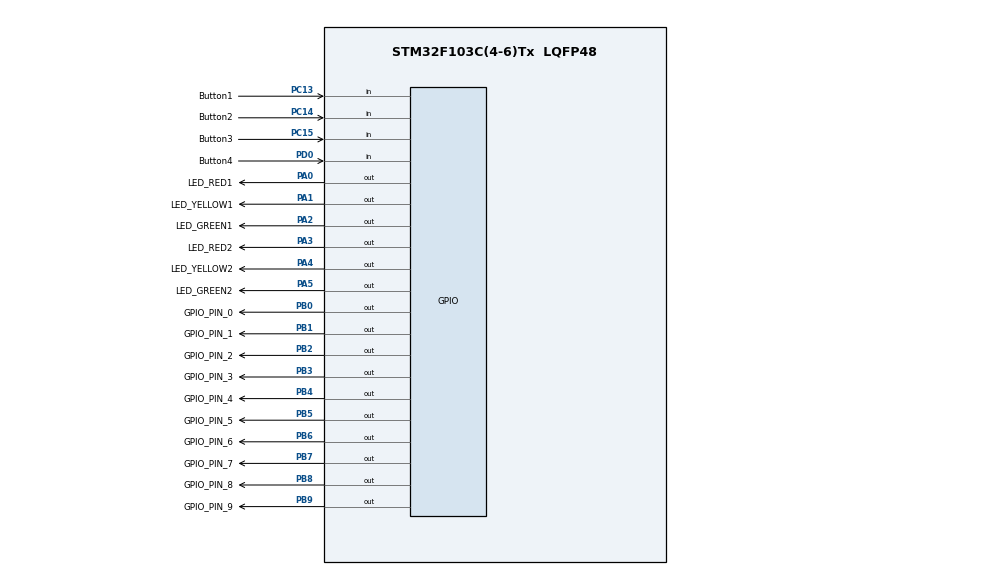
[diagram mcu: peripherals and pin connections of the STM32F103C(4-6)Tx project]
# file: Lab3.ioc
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Mcu.Family=STM32F1
Mcu.Name=STM32F103C(4-6)Tx
Mcu.Package=LQFP48
NVIC.PriorityGroup=NVIC_PRIORITYGROUP_4
NVIC.TIM2_IRQn=true\:0\:0\:false\:false\:true\:true\:true
PA0-WKUP.GPIO_Label=LED_RED1
PA0-WKUP.Signal=GPIO_Output
PA1.GPIO_Label=LED_YELLOW1
PA1.Signal=GPIO_Output
PA13.Mode=Serial_Wire
PA13.Signal=SYS_JTMS-SWDIO
PA14.Mode=Serial_Wire
PA14.Signal=SYS_JTCK-SWCLK
PA2.GPIO_Label=LED_GREEN1
PA2.Signal=GPIO_Output
PA3.GPIO_Label=LED_RED2
PA3.Signal=GPIO_Output
PA4.GPIO_Label=LED_YELLOW2
PA4.Signal=GPIO_Output
PA5.GPIO_Label=LED_GREEN2
PA5.Signal=GPIO_Output
PB0.GPIO_Label=GPIO_PIN_0
PB0.PinState=GPIO_PIN_SET
PB0.Signal=GPIO_Output
PB1.GPIO_Label=GPIO_PIN_1
PB1.PinState=GPIO_PIN_SET
PB1.Signal=GPIO_Output
PB2.GPIO_Label=GPIO_PIN_2
PB2.PinState=GPIO_PIN_SET
PB2.Signal=GPIO_Output
PB3.GPIO_Label=GPIO_PIN_3
PB3.PinState=GPIO_PIN_SET
PB3.Signal=GPIO_Output
PB4.GPIO_Label=GPIO_PIN_4
PB4.PinState=GPIO_PIN_SET
PB4.Signal=GPIO_Output
PB5.GPIO_Label=GPIO_PIN_5
PB5.PinState=GPIO_PIN_SET
PB5.Signal=GPIO_Output
PB6.GPIO_Label=GPIO_PIN_6
PB6.PinState=GPIO_PIN_SET
PB6.Signal=GPIO_Output
PB7.GPIO_Label=GPIO_PIN_7
PB7.PinState=GPIO_PIN_SET
PB7.Signal=GPIO_Output
PB8.GPIO_Label=GPIO_PIN_8
PB8.PinState=GPIO_PIN_SET
PB8.Signal=GPIO_Output
PB9.GPIO_Label=GPIO_PIN_9
PB9.PinState=GPIO_PIN_SET
PB9.Signal=GPIO_Output
PC13-TAMPER-RTC.GPIO_Label=Button1
PC13-TAMPER-RTC.GPIO_PuPd=GPIO_PULLUP
PC13-TAMPER-RTC.Signal=GPIO_Input
PC14-OSC32_IN.GPIO_Label=Button2
PC14-OSC32_IN.GPIO_PuPd=GPIO_PULLUP
PC14-OSC32_IN.Signal=GPIO_Input
PC15-OSC32_OUT.GPIO_Label=Button3
PC15-OSC32_OUT.GPIO_PuPd=GPIO_PULLUP
PC15-OSC32_OUT.Signal=GPIO_Input
PD0-OSC_IN.GPIO_Label=Button4
PD0-OSC_IN.GPIO_PuPd=GPIO_PULLUP
PD0-OSC_IN.Signal=GPIO_Input
ProjectManager.HeapSize=0x200
ProjectManager.StackSize=0x400
ProjectManager.TargetToolchain=STM32CubeIDE
RCC.APB1Freq_Value=8000000
RCC.APB2Freq_Value=8000000
TIM2.Period=9
TIM2.Prescaler=7999
VP_TIM2_VS_ClockSourceINT.Mode=Internal
board=custom

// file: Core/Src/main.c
/* USER CODE BEGIN Header */
/**
  ******************************************************************************
  * @file           : main.c
  * @brief          : Main program body
  ******************************************************************************
  * @attention
  *
  * <h2><center>&copy; Copyright (c) 2023 STMicroelectronics.
  * All rights reserved.</center></h2>
  *
  * This software component is licensed by ST under BSD 3-Clause license,
  * the "License"; You may not use this file except in compliance with the
  * License. You may obtain a copy of the License at:
  *                        opensource.org/licenses/BSD-3-Clause
  *
  ******************************************************************************
  */
/* USER CODE END Header */
#include "main.h"

/* USER CODE BEGIN Includes */
#include "software_timer.h"
#include "button.h"
#include "fsm_automatic.h"
#include "fsm_manual.h"
#include "display_7LED.h"
/* USER CODE END Includes */

TIM_HandleTypeDef htim2;

void SystemClock_Config(void);
static void MX_GPIO_Init(void);
static void MX_TIM2_Init(void);

int main(void)
{

  /* MCU Configuration--------------------------------------------------------*/

  /* Reset of all peripherals, Initializes the Flash interface and the Systick. */
  HAL_Init();

  /* Configure the system clock */
  SystemClock_Config();

  /* Initialize all configured peripherals */
  MX_GPIO_Init();
  MX_TIM2_Init();
  /* USER CODE BEGIN 2 */
  HAL_TIM_Base_Start_IT(&htim2);
  /* USER CODE END 2 */

  /* Infinite loop */
  /* USER CODE BEGIN WHILE */
  status = INIT;
  while (1)
  {
	  fsm_automatic_run();
    /* USER CODE END WHILE */

  }
}

void SystemClock_Config(void)
{
  RCC_OscInitTypeDef RCC_OscInitStruct = {0};
  RCC_ClkInitTypeDef RCC_ClkInitStruct = {0};

  /** Initializes the RCC Oscillators according to the specified parameters
  * in the RCC_OscInitTypeDef structure.
  */
  RCC_OscInitStruct.OscillatorType = RCC_OSCILLATORTYPE_HSI;
  RCC_OscInitStruct.HSIState = RCC_HSI_ON;
  RCC_OscInitStruct.HSICalibrationValue = RCC_HSICALIBRATION_DEFAULT;
  RCC_OscInitStruct.PLL.PLLState = RCC_PLL_NONE;
  if (HAL_RCC_OscConfig(&RCC_OscInitStruct) != HAL_OK)
  {
    Error_Handler();
  }
  /** Initializes the CPU, AHB and APB buses clocks
  */
  RCC_ClkInitStruct.ClockType = RCC_CLOCKTYPE_HCLK|RCC_CLOCKTYPE_SYSCLK
                              |RCC_CLOCKTYPE_PCLK1|RCC_CLOCKTYPE_PCLK2;
  RCC_ClkInitStruct.SYSCLKSource = RCC_SYSCLKSOURCE_HSI;
  RCC_ClkInitStruct.AHBCLKDivider = RCC_SYSCLK_DIV1;
  RCC_ClkInitStruct.APB1CLKDivider = RCC_HCLK_DIV1;
  RCC_ClkInitStruct.APB2CLKDivider = RCC_HCLK_DIV1;

  if (HAL_RCC_ClockConfig(&RCC_ClkInitStruct, FLASH_LATENCY_0) != HAL_OK)
  {
    Error_Handler();
  }
}

static void MX_TIM2_Init(void)
{

  TIM_ClockConfigTypeDef sClockSourceConfig = {0};
  TIM_MasterConfigTypeDef sMasterConfig = {0};

  htim2.Instance = TIM2;
  htim2.Init.Prescaler = 7999;
  htim2.Init.CounterMode = TIM_COUNTERMODE_UP;
  htim2.Init.Period = 9;
  htim2.Init.ClockDivision = TIM_CLOCKDIVISION_DIV1;
  htim2.Init.AutoReloadPreload = TIM_AUTORELOAD_PRELOAD_DISABLE;
  if (HAL_TIM_Base_Init(&htim2) != HAL_OK)
  {
    Error_Handler();
  }
  sClockSourceConfig.ClockSource = TIM_CLOCKSOURCE_INTERNAL;
  if (HAL_TIM_ConfigClockSource(&htim2, &sClockSourceConfig) != HAL_OK)
  {
    Error_Handler();
  }
  sMasterConfig.MasterOutputTrigger = TIM_TRGO_RESET;
  sMasterConfig.MasterSlaveMode = TIM_MASTERSLAVEMODE_DISABLE;
  if (HAL_TIMEx_MasterConfigSynchronization(&htim2, &sMasterConfig) != HAL_OK)
  {
    Error_Handler();
  }

}

static void MX_GPIO_Init(void)
{
  GPIO_InitTypeDef GPIO_InitStruct = {0};

  /* GPIO Ports Clock Enable */
  __HAL_RCC_GPIOC_CLK_ENABLE();
  __HAL_RCC_GPIOD_CLK_ENABLE();
  __HAL_RCC_GPIOA_CLK_ENABLE();
  __HAL_RCC_GPIOB_CLK_ENABLE();

  /*Configure GPIO pin Output Level */
  HAL_GPIO_WritePin(GPIOA, LED_RED1_Pin|LED_YELLOW1_Pin|LED_GREEN1_Pin|LED_RED2_Pin
                          |LED_YELLOW2_Pin|LED_GREEN2_Pin, GPIO_PIN_RESET);

  /*Configure GPIO pin Output Level */
  HAL_GPIO_WritePin(GPIOB, GPIO_PIN_0_Pin|GPIO_PIN_1_Pin|GPIO_PIN_2_Pin|GPIO_PIN_3_Pin
                          |GPIO_PIN_4_Pin|GPIO_PIN_5_Pin|GPIO_PIN_6_Pin|GPIO_PIN_7_Pin
                          |GPIO_PIN_8_Pin|GPIO_PIN_9_Pin, GPIO_PIN_SET);

  /*Configure GPIO pins : Button1_Pin Button2_Pin Button3_Pin */
  GPIO_InitStruct.Pin = Button1_Pin|Button2_Pin|Button3_Pin;
  GPIO_InitStruct.Mode = GPIO_MODE_INPUT;
  GPIO_InitStruct.Pull = GPIO_PULLUP;
  HAL_GPIO_Init(GPIOC, &GPIO_InitStruct);

  /*Configure GPIO pin : Button4_Pin */
  GPIO_InitStruct.Pin = Button4_Pin;
  GPIO_InitStruct.Mode = GPIO_MODE_INPUT;
  GPIO_InitStruct.Pull = GPIO_PULLUP;
  HAL_GPIO_Init(Button4_GPIO_Port, &GPIO_InitStruct);

  /*Configure GPIO pins : LED_RED1_Pin LED_YELLOW1_Pin LED_GREEN1_Pin LED_RED2_Pin
                           LED_YELLOW2_Pin LED_GREEN2_Pin */
  GPIO_InitStruct.Pin = LED_RED1_Pin|LED_YELLOW1_Pin|LED_GREEN1_Pin|LED_RED2_Pin
                          |LED_YELLOW2_Pin|LED_GREEN2_Pin;
  GPIO_InitStruct.Mode = GPIO_MODE_OUTPUT_PP;
  GPIO_InitStruct.Pull = GPIO_NOPULL;
  GPIO_InitStruct.Speed = GPIO_SPEED_FREQ_LOW;
  HAL_GPIO_Init(GPIOA, &GPIO_InitStruct);

  /*Configure GPIO pins : PBPin PBPin PBPin PBPin
                           PBPin PBPin PBPin PBPin
                           PBPin PBPin */
  GPIO_InitStruct.Pin = GPIO_PIN_0_Pin|GPIO_PIN_1_Pin|GPIO_PIN_2_Pin|GPIO_PIN_3_Pin
                          |GPIO_PIN_4_Pin|GPIO_PIN_5_Pin|GPIO_PIN_6_Pin|GPIO_PIN_7_Pin
                          |GPIO_PIN_8_Pin|GPIO_PIN_9_Pin;
  GPIO_InitStruct.Mode = GPIO_MODE_OUTPUT_PP;
  GPIO_InitStruct.Pull = GPIO_NOPULL;
  GPIO_InitStruct.Speed = GPIO_SPEED_FREQ_LOW;
  HAL_GPIO_Init(GPIOB, &GPIO_InitStruct);

  /*Configure peripheral I/O remapping */
  __HAL_AFIO_REMAP_PD01_ENABLE();

}

/* USER CODE BEGIN 4 */
void HAL_TIM_PeriodElapsedCallback(TIM_HandleTypeDef *htim){
	timerRun();
	getButton1Input();
	getButton2Input();
	getButton3Input();
	getButton4Input();
}
/* USER CODE END 4 */

void Error_Handler(void)
{
  __disable_irq();
  while (1)
  {
  }
}

/************************ (C) COPYRIGHT STMicroelectronics *****END OF FILE****/
